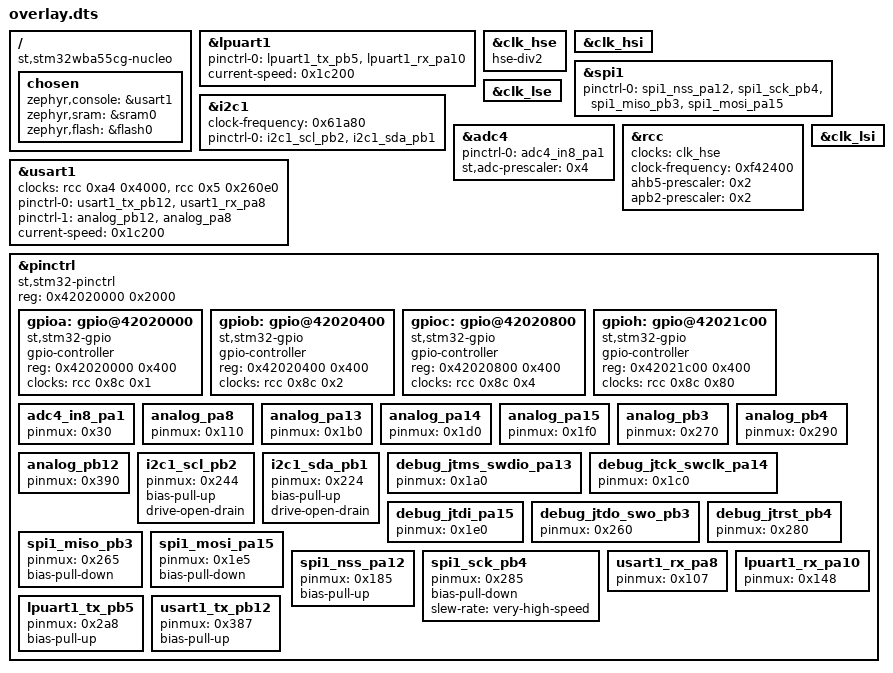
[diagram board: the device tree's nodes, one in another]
/ {
	compatible = "st,stm32wba55cg-nucleo";
	chosen {
		zephyr,console = &usart1;
		zephyr,sram = &sram0;
		zephyr,flash = &flash0;
	};
};
&lpuart1{
	status = "okay";
	pinctrl-0 = < &lpuart1_tx_pb5 &lpuart1_rx_pa10 >;
	pinctrl-names = "default";
	current-speed = < 0x1c200 >;
};
&clk_hse{
	status = "okay";
	hse-div2;
};
&clk_hsi{
	status = "okay";
};
&spi1{
	status = "okay";
	pinctrl-0 = < &spi1_nss_pa12 &spi1_sck_pb4 &spi1_miso_pb3 &spi1_mosi_pa15 >;
	pinctrl-names = "default";
};
&i2c1{
	clock-frequency = < 0x61a80 >;
	status = "okay";
	pinctrl-0 = < &i2c1_scl_pb2 &i2c1_sda_pb1 >;
	pinctrl-names = "default";
};
&clk_lse{
	status = "okay";
};
&adc4{
	status = "okay";
	pinctrl-0 = < &adc4_in8_pa1 >;
	pinctrl-names = "default";
	st,adc-prescaler = < 0x4 >;
};
&usart1{
	clocks = < &rcc 0xa4 0x4000 >, < &rcc 0x5 0x260e0 >;
	status = "okay";
	pinctrl-0 = < &usart1_tx_pb12 &usart1_rx_pa8 >;
	pinctrl-1 = < &analog_pb12 &analog_pa8 >;
	pinctrl-names = "default", "sleep";
	current-speed = < 0x1c200 >;
};
&rcc{
	clocks = < &clk_hse >;
	clock-frequency = < 0xf42400 >;
	ahb5-prescaler = < 0x2 >;
	apb2-prescaler = < 0x2 >;
};
&clk_lsi{
	status = "okay";
};
&pinctrl{
	compatible = "st,stm32-pinctrl";
	#address-cells = < 0x1 >;
	#size-cells = < 0x1 >;
	reg = < 0x42020000 0x2000 >;
	gpioa: gpio@42020000 {
		compatible = "st,stm32-gpio";
		gpio-controller;
		#gpio-cells = < 0x2 >;
		reg = < 0x42020000 0x400 >;
		clocks = < &rcc 0x8c 0x1 >;
	};
	gpiob: gpio@42020400 {
		compatible = "st,stm32-gpio";
		gpio-controller;
		#gpio-cells = < 0x2 >;
		reg = < 0x42020400 0x400 >;
		clocks = < &rcc 0x8c 0x2 >;
	};
	gpioc: gpio@42020800 {
		compatible = "st,stm32-gpio";
		gpio-controller;
		#gpio-cells = < 0x2 >;
		reg = < 0x42020800 0x400 >;
		clocks = < &rcc 0x8c 0x4 >;
	};
	gpioh: gpio@42021c00 {
		compatible = "st,stm32-gpio";
		gpio-controller;
		#gpio-cells = < 0x2 >;
		reg = < 0x42021c00 0x400 >;
		clocks = < &rcc 0x8c 0x80 >;
	};
	adc4_in8_pa1: adc4_in8_pa1 {
		pinmux = < 0x30 >;
	};
	analog_pa8: analog_pa8 {
		pinmux = < 0x110 >;
	};
	analog_pa13: analog_pa13 {
		pinmux = < 0x1b0 >;
	};
	analog_pa14: analog_pa14 {
		pinmux = < 0x1d0 >;
	};
	analog_pa15: analog_pa15 {
		pinmux = < 0x1f0 >;
	};
	analog_pb3: analog_pb3 {
		pinmux = < 0x270 >;
	};
	analog_pb4: analog_pb4 {
		pinmux = < 0x290 >;
	};
	analog_pb12: analog_pb12 {
		pinmux = < 0x390 >;
	};
	i2c1_scl_pb2: i2c1_scl_pb2 {
		pinmux = < 0x244 >;
		bias-pull-up;
		drive-open-drain;
	};
	i2c1_sda_pb1: i2c1_sda_pb1 {
		pinmux = < 0x224 >;
		bias-pull-up;
		drive-open-drain;
	};
	debug_jtms_swdio_pa13: debug_jtms_swdio_pa13 {
		pinmux = < 0x1a0 >;
	};
	debug_jtck_swclk_pa14: debug_jtck_swclk_pa14 {
		pinmux = < 0x1c0 >;
	};
	debug_jtdi_pa15: debug_jtdi_pa15 {
		pinmux = < 0x1e0 >;
	};
	debug_jtdo_swo_pb3: debug_jtdo_swo_pb3 {
		pinmux = < 0x260 >;
	};
	debug_jtrst_pb4: debug_jtrst_pb4 {
		pinmux = < 0x280 >;
	};
	spi1_miso_pb3: spi1_miso_pb3 {
		pinmux = < 0x265 >;
		bias-pull-down;
	};
	spi1_mosi_pa15: spi1_mosi_pa15 {
		pinmux = < 0x1e5 >;
		bias-pull-down;
	};
	spi1_nss_pa12: spi1_nss_pa12 {
		pinmux = < 0x185 >;
		bias-pull-up;
	};
	spi1_sck_pb4: spi1_sck_pb4 {
		pinmux = < 0x285 >;
		bias-pull-down;
		slew-rate = "very-high-speed";
	};
	usart1_rx_pa8: usart1_rx_pa8 {
		pinmux = < 0x107 >;
	};
	lpuart1_rx_pa10: lpuart1_rx_pa10 {
		pinmux = < 0x148 >;
	};
	lpuart1_tx_pb5: lpuart1_tx_pb5 {
		pinmux = < 0x2a8 >;
		bias-pull-up;
	};
	usart1_tx_pb12: usart1_tx_pb12 {
		pinmux = < 0x387 >;
		bias-pull-up;
	};
};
